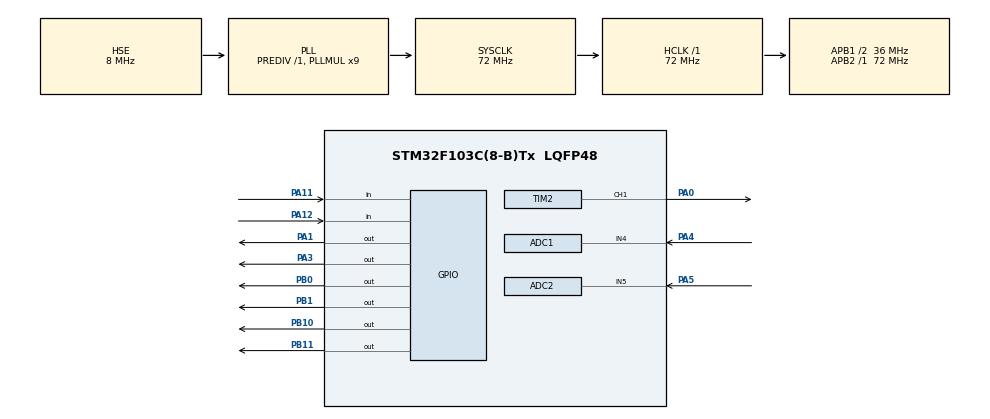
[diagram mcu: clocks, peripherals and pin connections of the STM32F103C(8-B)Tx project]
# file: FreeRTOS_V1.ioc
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ADC1.Channel-2\#ChannelRegularConversion=ADC_CHANNEL_4
ADC1.NbrOfConversionFlag=1
ADC1.Rank-2\#ChannelRegularConversion=1
ADC1.SamplingTime-2\#ChannelRegularConversion=ADC_SAMPLETIME_1CYCLE_5
ADC1.master=1
ADC2.Channel-0\#ChannelRegularConversion=ADC_CHANNEL_5
ADC2.ContinuousConvMode=ENABLE
ADC2.NbrOfConversionFlag=1
ADC2.Rank-0\#ChannelRegularConversion=1
ADC2.SamplingTime-0\#ChannelRegularConversion=ADC_SAMPLETIME_1CYCLE_5
FREERTOS.Queues01=ThrottleQueue,16,uint16_t,0,Dynamic,NULL,NULL;BreakQueue,16,uint16_t,0,Dynamic,NULL,NULL;GearQueue,16,char,0,Dynamic,NULL,NULL;DisplayQueue,16,uint16_t,0,Dynamic,NULL,NULL
FREERTOS.Tasks01=Throttle,24,128,ThrottleInput,Default,NULL,Dynamic,NULL,NULL;Break,8,128,BreakInput,Default,NULL,Dynamic,NULL,NULL;Gear,8,128,GearInput,Default,NULL,Dynamic,NULL,NULL;Data,8,128,DataInput,Default,NULL,Dynamic,NULL,NULL;Display,8,128,DisplayInput,Default,NULL,Dynamic,NULL,NULL
FREERTOS.configTOTAL_HEAP_SIZE=4096
Mcu.Family=STM32F1
Mcu.Name=STM32F103C(8-B)Tx
Mcu.Package=LQFP48
NVIC.PriorityGroup=NVIC_PRIORITYGROUP_4
NVIC.TIM1_UP_IRQn=true\:15\:0\:false\:false\:true\:false\:false\:true\:true
NVIC.TimeBase=TIM1_UP_IRQn
NVIC.TimeBaseIP=TIM1
PA0-WKUP.Signal=S_TIM2_CH1_ETR
PA1.Signal=GPIO_Output
PA11.Signal=GPIO_Input
PA12.Signal=GPIO_Input
PA13.Mode=Serial_Wire
PA13.Signal=SYS_JTMS-SWDIO
PA14.Mode=Serial_Wire
PA14.Signal=SYS_JTCK-SWCLK
PA3.Signal=GPIO_Output
PA4.Signal=ADCx_IN4
PA5.Signal=ADCx_IN5
PB0.Signal=GPIO_Output
PB1.Signal=GPIO_Output
PB10.Signal=GPIO_Output
PB11.Signal=GPIO_Output
PD0-OSC_IN.Mode=HSE-External-Oscillator
PD0-OSC_IN.Signal=RCC_OSC_IN
PD1-OSC_OUT.Mode=HSE-External-Oscillator
PD1-OSC_OUT.Signal=RCC_OSC_OUT
ProjectManager.HeapSize=0x200
ProjectManager.StackSize=0x400
ProjectManager.TargetToolchain=STM32CubeIDE
RCC.ADCPresc=RCC_ADCPCLK2_DIV6
RCC.AHBFreq_Value=72000000
RCC.APB1CLKDivider=RCC_HCLK_DIV2
RCC.APB1Freq_Value=36000000
RCC.APB1TimFreq_Value=72000000
RCC.APB2Freq_Value=72000000
RCC.APB2TimFreq_Value=72000000
RCC.HCLKFreq_Value=72000000
RCC.PLLMUL=RCC_PLL_MUL9
RCC.PLLSourceVirtual=RCC_PLLSOURCE_HSE
RCC.SYSCLKFreq_VALUE=72000000
RCC.SYSCLKSource=RCC_SYSCLKSOURCE_PLLCLK
RCC.USBFreq_Value=72000000
SH.ADCx_IN4.0=ADC1_IN4,IN4
SH.ADCx_IN5.0=ADC2_IN5,IN5
SH.S_TIM2_CH1_ETR.0=TIM2_CH1,PWM Generation1 CH1
TIM2.Channel-PWM\ Generation1\ CH1=TIM_CHANNEL_1
VP_FREERTOS_VS_CMSIS_V2.Mode=CMSIS_V2
VP_SYS_VS_tim1.Mode=TIM1
VP_TIM2_VS_ClockSourceINT.Mode=Internal
board=custom

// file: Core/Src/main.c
/* USER CODE BEGIN Header */
/**
  ******************************************************************************
  * @file           : main.c
  * @brief          : Main program body
  ******************************************************************************
  * @attention
  *
  * Copyright (c) 2022 STMicroelectronics.
  * All rights reserved.
  *
  * This software is licensed under terms that can be found in the LICENSE file
  * in the root directory of this software component.
  * If no LICENSE file comes with this software, it is provided AS-IS.
  *
  ******************************************************************************
  */
/* USER CODE END Header */
#include "main.h"
#include "cmsis_os.h"

/* USER CODE BEGIN Includes */
#include "lcd.h"
/* USER CODE END Includes */

ADC_HandleTypeDef hadc1;
ADC_HandleTypeDef hadc2;

TIM_HandleTypeDef htim2;

/* Definitions for Throttle */
osThreadId_t ThrottleHandle;
const osThreadAttr_t Throttle_attributes = {
  .name = "Throttle",
  .stack_size = 128 * 4,
  .priority = (osPriority_t) osPriorityNormal,
};
/* Definitions for Break */
osThreadId_t BreakHandle;
const osThreadAttr_t Break_attributes = {
  .name = "Break",
  .stack_size = 128 * 4,
  .priority = (osPriority_t) osPriorityLow,
};
/* Definitions for Gear */
osThreadId_t GearHandle;
const osThreadAttr_t Gear_attributes = {
  .name = "Gear",
  .stack_size = 128 * 4,
  .priority = (osPriority_t) osPriorityLow,
};
/* Definitions for Data */
osThreadId_t DataHandle;
const osThreadAttr_t Data_attributes = {
  .name = "Data",
  .stack_size = 128 * 4,
  .priority = (osPriority_t) osPriorityLow,
};
/* Definitions for Display */
osThreadId_t DisplayHandle;
const osThreadAttr_t Display_attributes = {
  .name = "Display",
  .stack_size = 128 * 4,
  .priority = (osPriority_t) osPriorityLow,
};
/* Definitions for ThrottleQueue */
osMessageQueueId_t ThrottleQueueHandle;
const osMessageQueueAttr_t ThrottleQueue_attributes = {
  .name = "ThrottleQueue"
};
/* Definitions for BreakQueue */
osMessageQueueId_t BreakQueueHandle;
const osMessageQueueAttr_t BreakQueue_attributes = {
  .name = "BreakQueue"
};
/* Definitions for GearQueue */
osMessageQueueId_t GearQueueHandle;
const osMessageQueueAttr_t GearQueue_attributes = {
  .name = "GearQueue"
};
/* Definitions for DisplayQueue */
osMessageQueueId_t DisplayQueueHandle;
const osMessageQueueAttr_t DisplayQueue_attributes = {
  .name = "DisplayQueue"
};

void SystemClock_Config(void);
static void MX_GPIO_Init(void);
static void MX_ADC1_Init(void);
static void MX_ADC2_Init(void);
static void MX_TIM2_Init(void);
void ThrottleInput(void *argument);
void BreakInput(void *argument);
void GearInput(void *argument);
void DataInput(void *argument);
void DisplayInput(void *argument);

int main(void)
{

  /* MCU Configuration--------------------------------------------------------*/

  /* Reset of all peripherals, Initializes the Flash interface and the Systick. */
  HAL_Init();

  /* Configure the system clock */
  SystemClock_Config();

  /* Initialize all configured peripherals */
  MX_GPIO_Init();
  MX_ADC1_Init();
  MX_ADC2_Init();
  MX_TIM2_Init();

  /* Init scheduler */
  osKernelInitialize();

  /* Create the queue(s) */
  /* creation of ThrottleQueue */
  ThrottleQueueHandle = osMessageQueueNew (16, sizeof(uint16_t), &ThrottleQueue_attributes);

  /* creation of BreakQueue */
  BreakQueueHandle = osMessageQueueNew (16, sizeof(uint16_t), &BreakQueue_attributes);

  /* creation of GearQueue */
  GearQueueHandle = osMessageQueueNew (16, sizeof(char), &GearQueue_attributes);

  /* creation of DisplayQueue */
  DisplayQueueHandle = osMessageQueueNew (16, sizeof(uint16_t), &DisplayQueue_attributes);

  /* Create the thread(s) */
  /* creation of Throttle */
  ThrottleHandle = osThreadNew(ThrottleInput, NULL, &Throttle_attributes);

  /* creation of Break */
  BreakHandle = osThreadNew(BreakInput, NULL, &Break_attributes);

  /* creation of Gear */
  GearHandle = osThreadNew(GearInput, NULL, &Gear_attributes);

  /* creation of Data */
  DataHandle = osThreadNew(DataInput, NULL, &Data_attributes);

  /* creation of Display */
  DisplayHandle = osThreadNew(DisplayInput, NULL, &Display_attributes);

  /* Start scheduler */
  osKernelStart();

  /* We should never get here as control is now taken by the scheduler */
  /* Infinite loop */
  while (1)
  {

  }
}

void SystemClock_Config(void)
{
  RCC_OscInitTypeDef RCC_OscInitStruct = {0};
  RCC_ClkInitTypeDef RCC_ClkInitStruct = {0};
  RCC_PeriphCLKInitTypeDef PeriphClkInit = {0};

  /** Initializes the RCC Oscillators according to the specified parameters
  * in the RCC_OscInitTypeDef structure.
  */
  RCC_OscInitStruct.OscillatorType = RCC_OSCILLATORTYPE_HSE;
  RCC_OscInitStruct.HSEState = RCC_HSE_ON;
  RCC_OscInitStruct.HSEPredivValue = RCC_HSE_PREDIV_DIV1;
  RCC_OscInitStruct.HSIState = RCC_HSI_ON;
  RCC_OscInitStruct.PLL.PLLState = RCC_PLL_ON;
  RCC_OscInitStruct.PLL.PLLSource = RCC_PLLSOURCE_HSE;
  RCC_OscInitStruct.PLL.PLLMUL = RCC_PLL_MUL9;
  if (HAL_RCC_OscConfig(&RCC_OscInitStruct) != HAL_OK)
  {
    Error_Handler();
  }

  /** Initializes the CPU, AHB and APB buses clocks
  */
  RCC_ClkInitStruct.ClockType = RCC_CLOCKTYPE_HCLK|RCC_CLOCKTYPE_SYSCLK
                              |RCC_CLOCKTYPE_PCLK1|RCC_CLOCKTYPE_PCLK2;
  RCC_ClkInitStruct.SYSCLKSource = RCC_SYSCLKSOURCE_PLLCLK;
  RCC_ClkInitStruct.AHBCLKDivider = RCC_SYSCLK_DIV1;
  RCC_ClkInitStruct.APB1CLKDivider = RCC_HCLK_DIV2;
  RCC_ClkInitStruct.APB2CLKDivider = RCC_HCLK_DIV1;

  if (HAL_RCC_ClockConfig(&RCC_ClkInitStruct, FLASH_LATENCY_2) != HAL_OK)
  {
    Error_Handler();
  }
  PeriphClkInit.PeriphClockSelection = RCC_PERIPHCLK_ADC;
  PeriphClkInit.AdcClockSelection = RCC_ADCPCLK2_DIV6;
  if (HAL_RCCEx_PeriphCLKConfig(&PeriphClkInit) != HAL_OK)
  {
    Error_Handler();
  }
}

static void MX_ADC1_Init(void)
{

  ADC_ChannelConfTypeDef sConfig = {0};

  /** Common config
  */
  hadc1.Instance = ADC1;
  hadc1.Init.ScanConvMode = ADC_SCAN_DISABLE;
  hadc1.Init.ContinuousConvMode = DISABLE;
  hadc1.Init.DiscontinuousConvMode = DISABLE;
  hadc1.Init.ExternalTrigConv = ADC_SOFTWARE_START;
  hadc1.Init.DataAlign = ADC_DATAALIGN_RIGHT;
  hadc1.Init.NbrOfConversion = 1;
  if (HAL_ADC_Init(&hadc1) != HAL_OK)
  {
    Error_Handler();
  }

  /** Configure Regular Channel
  */
  sConfig.Channel = ADC_CHANNEL_4;
  sConfig.Rank = ADC_REGULAR_RANK_1;
  sConfig.SamplingTime = ADC_SAMPLETIME_1CYCLE_5;
  if (HAL_ADC_ConfigChannel(&hadc1, &sConfig) != HAL_OK)
  {
    Error_Handler();
  }

}

static void MX_ADC2_Init(void)
{

  ADC_ChannelConfTypeDef sConfig = {0};

  /** Common config
  */
  hadc2.Instance = ADC2;
  hadc2.Init.ScanConvMode = ADC_SCAN_DISABLE;
  hadc2.Init.ContinuousConvMode = ENABLE;
  hadc2.Init.DiscontinuousConvMode = DISABLE;
  hadc2.Init.ExternalTrigConv = ADC_SOFTWARE_START;
  hadc2.Init.DataAlign = ADC_DATAALIGN_RIGHT;
  hadc2.Init.NbrOfConversion = 1;
  if (HAL_ADC_Init(&hadc2) != HAL_OK)
  {
    Error_Handler();
  }

  /** Configure Regular Channel
  */
  sConfig.Channel = ADC_CHANNEL_5;
  sConfig.Rank = ADC_REGULAR_RANK_1;
  sConfig.SamplingTime = ADC_SAMPLETIME_1CYCLE_5;
  if (HAL_ADC_ConfigChannel(&hadc2, &sConfig) != HAL_OK)
  {
    Error_Handler();
  }

}

static void MX_TIM2_Init(void)
{

  TIM_ClockConfigTypeDef sClockSourceConfig = {0};
  TIM_MasterConfigTypeDef sMasterConfig = {0};
  TIM_OC_InitTypeDef sConfigOC = {0};

  htim2.Instance = TIM2;
  htim2.Init.Prescaler = 0;
  htim2.Init.CounterMode = TIM_COUNTERMODE_UP;
  htim2.Init.Period = 65535;
  htim2.Init.ClockDivision = TIM_CLOCKDIVISION_DIV1;
  htim2.Init.AutoReloadPreload = TIM_AUTORELOAD_PRELOAD_DISABLE;
  if (HAL_TIM_Base_Init(&htim2) != HAL_OK)
  {
    Error_Handler();
  }
  sClockSourceConfig.ClockSource = TIM_CLOCKSOURCE_INTERNAL;
  if (HAL_TIM_ConfigClockSource(&htim2, &sClockSourceConfig) != HAL_OK)
  {
    Error_Handler();
  }
  if (HAL_TIM_PWM_Init(&htim2) != HAL_OK)
  {
    Error_Handler();
  }
  sMasterConfig.MasterOutputTrigger = TIM_TRGO_RESET;
  sMasterConfig.MasterSlaveMode = TIM_MASTERSLAVEMODE_DISABLE;
  if (HAL_TIMEx_MasterConfigSynchronization(&htim2, &sMasterConfig) != HAL_OK)
  {
    Error_Handler();
  }
  sConfigOC.OCMode = TIM_OCMODE_PWM1;
  sConfigOC.Pulse = 0;
  sConfigOC.OCPolarity = TIM_OCPOLARITY_HIGH;
  sConfigOC.OCFastMode = TIM_OCFAST_DISABLE;
  if (HAL_TIM_PWM_ConfigChannel(&htim2, &sConfigOC, TIM_CHANNEL_1) != HAL_OK)
  {
    Error_Handler();
  }
  HAL_TIM_MspPostInit(&htim2);

}

static void MX_GPIO_Init(void)
{
  GPIO_InitTypeDef GPIO_InitStruct = {0};

  /* GPIO Ports Clock Enable */
  __HAL_RCC_GPIOD_CLK_ENABLE();
  __HAL_RCC_GPIOA_CLK_ENABLE();
  __HAL_RCC_GPIOB_CLK_ENABLE();

  /*Configure GPIO pin Output Level */
  HAL_GPIO_WritePin(GPIOA, GPIO_PIN_1|GPIO_PIN_3, GPIO_PIN_RESET);

  /*Configure GPIO pin Output Level */
  HAL_GPIO_WritePin(GPIOB, GPIO_PIN_0|GPIO_PIN_1|GPIO_PIN_10|GPIO_PIN_11, GPIO_PIN_RESET);

  /*Configure GPIO pins : PA1 PA3 */
  GPIO_InitStruct.Pin = GPIO_PIN_1|GPIO_PIN_3;
  GPIO_InitStruct.Mode = GPIO_MODE_OUTPUT_PP;
  GPIO_InitStruct.Pull = GPIO_NOPULL;
  GPIO_InitStruct.Speed = GPIO_SPEED_FREQ_LOW;
  HAL_GPIO_Init(GPIOA, &GPIO_InitStruct);

  /*Configure GPIO pins : PB0 PB1 PB10 PB11 */
  GPIO_InitStruct.Pin = GPIO_PIN_0|GPIO_PIN_1|GPIO_PIN_10|GPIO_PIN_11;
  GPIO_InitStruct.Mode = GPIO_MODE_OUTPUT_PP;
  GPIO_InitStruct.Pull = GPIO_NOPULL;
  GPIO_InitStruct.Speed = GPIO_SPEED_FREQ_LOW;
  HAL_GPIO_Init(GPIOB, &GPIO_InitStruct);

  /*Configure GPIO pins : PA11 PA12 */
  GPIO_InitStruct.Pin = GPIO_PIN_11|GPIO_PIN_12;
  GPIO_InitStruct.Mode = GPIO_MODE_INPUT;
  GPIO_InitStruct.Pull = GPIO_NOPULL;
  HAL_GPIO_Init(GPIOA, &GPIO_InitStruct);

}

void ThrottleInput(void *argument)
{
  for(;;)
  {
    osDelay(1);
  }
}

void BreakInput(void *argument)
{
  for(;;)
  {
    osDelay(1);
  }
}

void GearInput(void *argument)
{
  for(;;)
  {
    osDelay(1);
  }
}

void DataInput(void *argument)
{
  for(;;)
  {
    osDelay(1);
  }
}

void DisplayInput(void *argument)
{
  /* USER CODE BEGIN DisplayInput */
	// Lcd_PortType ports[] = { D4_GPIO_Port, D5_GPIO_Port, D6_GPIO_Port, D7_GPIO_Port };
	Lcd_PortType ports[] = { GPIOB, GPIOB, GPIOB, GPIOB };
	// Lcd_PinType pins[] = {D4_Pin, D5_Pin, D6_Pin, D7_Pin};
	Lcd_PinType pins[] = {GPIO_PIN_0, GPIO_PIN_1, GPIO_PIN_10, GPIO_PIN_11};
	Lcd_HandleTypeDef lcd;
	// Lcd_create(ports, pins, RS_GPIO_Port, RS_Pin, EN_GPIO_Port, EN_Pin, LCD_4_BIT_MODE);
	lcd = Lcd_create(ports, pins, GPIOA, GPIO_PIN_1, GPIOA, GPIO_PIN_3, LCD_4_BIT_MODE);
  /* Infinite loop */
  for(;;)
  {
	  Lcd_cursor(&lcd, 0,0);
	  Lcd_string(&lcd, "Testing LCD");

    osDelay(1);
  }  /* USER CODE END DisplayInput */
}

void HAL_TIM_PeriodElapsedCallback(TIM_HandleTypeDef *htim)
{
  if (htim->Instance == TIM1) {
    HAL_IncTick();
  }
}

void Error_Handler(void)
{
  __disable_irq();
  while (1)
  {
  }
}
